VERSION ""

NS_ :

BS_:

BU_: Brake Body

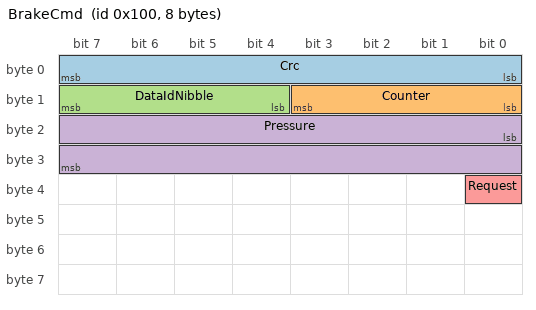
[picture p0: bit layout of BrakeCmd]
BO_ 256 BrakeCmd: 8 Brake
 SG_ Crc : 0|8@1+ (1,0) [0|255] "" Body
 SG_ Counter : 8|4@1+ (1,0) [0|15] "" Body
 SG_ DataIdNibble : 12|4@1+ (1,0) [0|15] "" Body
 SG_ Pressure : 16|16@1+ (0.1,0) [0|6553.5] "bar" Body
 SG_ Request : 32|1@1+ (1,0) [0|1] "" Body

BO_ 2147484160 SafetyStatus: 16 Body
 SG_ Crc : 0|16@1+ (1,0) [0|65535] "" Brake
 SG_ Counter : 16|8@1+ (1,0) [0|255] "" Brake
 SG_ Speed : 24|16@1+ (0.01,0) [0|655.35] "km/h" Brake

BA_DEF_ BO_ "VFrameFormat" ENUM "StandardCAN","ExtendedCAN","reserved","J1939PG","reserved","reserved","reserved","reserved","reserved","reserved","reserved","reserved","reserved","reserved","StandardCAN_FD","ExtendedCAN_FD";
BA_DEF_DEF_ "VFrameFormat" "StandardCAN";
BA_ "VFrameFormat" BO_ 2147484160 15;
